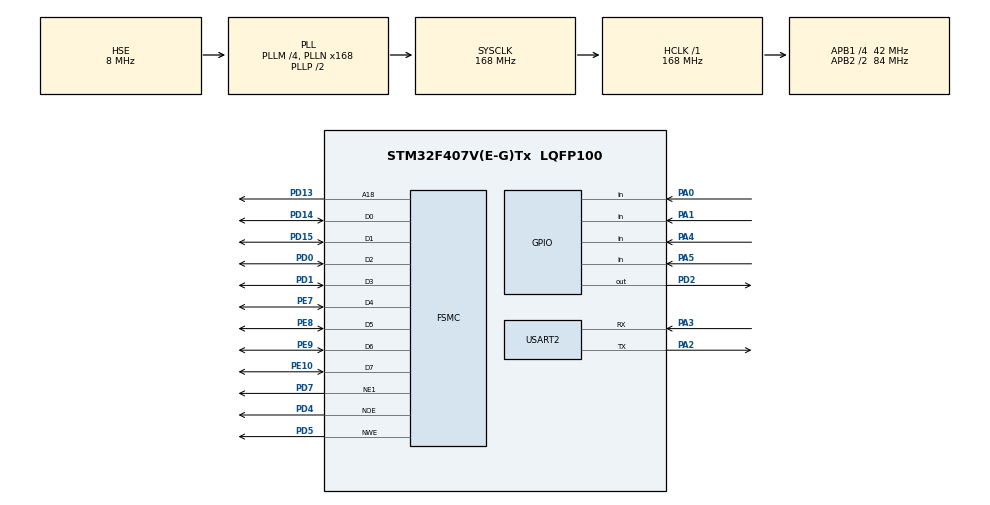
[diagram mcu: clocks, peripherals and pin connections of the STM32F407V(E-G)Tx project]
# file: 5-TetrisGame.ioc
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Mcu.Family=STM32F4
Mcu.Name=STM32F407V(E-G)Tx
Mcu.Package=LQFP100
NVIC.HASH_RNG_IRQn=true\:0\:0\:false\:false\:true\:true\:true
NVIC.PriorityGroup=NVIC_PRIORITYGROUP_4
NVIC.TIM2_IRQn=true\:0\:0\:false\:false\:true\:true\:true
PA0-WKUP.Signal=GPIO_Input
PA1.Signal=GPIO_Input
PA13.Mode=Serial_Wire
PA13.Signal=SYS_JTMS-SWDIO
PA14.Mode=Serial_Wire
PA14.Signal=SYS_JTCK-SWCLK
PA2.Mode=Asynchronous
PA2.Signal=USART2_TX
PA3.Mode=Asynchronous
PA3.Signal=USART2_RX
PA4.Signal=GPIO_Input
PA5.Signal=GPIO_Input
PD0.Mode=8b-d1
PD0.Signal=FSMC_D2
PD1.Mode=8b-d1
PD1.Signal=FSMC_D3
PD13.Mode=A18_1
PD13.Signal=FSMC_A18
PD14.Mode=8b-d1
PD14.Signal=FSMC_D0
PD15.Mode=8b-d1
PD15.Signal=FSMC_D1
PD2.Signal=GPIO_Output
PD4.Mode=Lcd1
PD4.Signal=FSMC_NOE
PD5.Mode=Lcd1
PD5.Signal=FSMC_NWE
PD7.Mode=NorPsramChipSelect1_1
PD7.Signal=FSMC_NE1
PE10.Mode=8b-d1
PE10.Signal=FSMC_D7
PE7.Mode=8b-d1
PE7.Signal=FSMC_D4
PE8.Mode=8b-d1
PE8.Signal=FSMC_D5
PE9.Mode=8b-d1
PE9.Signal=FSMC_D6
PH0-OSC_IN.Mode=HSE-External-Oscillator
PH0-OSC_IN.Signal=RCC_OSC_IN
PH1-OSC_OUT.Mode=HSE-External-Oscillator
PH1-OSC_OUT.Signal=RCC_OSC_OUT
ProjectManager.HeapSize=0x200
ProjectManager.StackSize=0x400
ProjectManager.TargetToolchain=TrueSTUDIO
RCC.48MHZClocksFreq_Value=48000000
RCC.AHBFreq_Value=168000000
RCC.APB1CLKDivider=RCC_HCLK_DIV4
RCC.APB1Freq_Value=42000000
RCC.APB1TimFreq_Value=84000000
RCC.APB2CLKDivider=RCC_HCLK_DIV2
RCC.APB2Freq_Value=84000000
RCC.APB2TimFreq_Value=168000000
RCC.CortexFreq_Value=168000000
RCC.HCLKFreq_Value=168000000
RCC.HSE_VALUE=8000000
RCC.HSI_VALUE=16000000
RCC.LSE_VALUE=32768
RCC.PLLM=4
RCC.PLLN=168
RCC.PLLQ=7
RCC.PLLSourceVirtual=RCC_PLLSOURCE_HSE
RCC.SYSCLKFreq_VALUE=168000000
RCC.SYSCLKSource=RCC_SYSCLKSOURCE_PLLCLK
RCC.VCOOutputFreq_Value=336000000
TIM2.Period=400
TIM2.Prescaler=16799
USART2.VirtualMode=VM_ASYNC
VP_RNG_VS_RNG.Mode=RNG_Activate
VP_TIM2_VS_ClockSourceINT.Mode=Internal
board=custom

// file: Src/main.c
/* USER CODE BEGIN Header */
/**
  ******************************************************************************
  * @file           : main.c
  * @brief          : Main program body
  ******************************************************************************
  * @attention
  *
  * <h2><center>&copy; Copyright (c) 2021 STMicroelectronics.
  * All rights reserved.</center></h2>
  *
  * This software component is licensed by ST under BSD 3-Clause license,
  * the "License"; You may not use this file except in compliance with the
  * License. You may obtain a copy of the License at:
  *                        opensource.org/licenses/BSD-3-Clause
  *
  ******************************************************************************
  */
/* USER CODE END Header */

#include "main.h"

/* USER CODE BEGIN Includes */
#include "ili9341.h"
/* USER CODE END Includes */

RNG_HandleTypeDef hrng;

TIM_HandleTypeDef htim2;

UART_HandleTypeDef huart2;

SRAM_HandleTypeDef hsram1;

void SystemClock_Config(void);
static void MX_GPIO_Init(void);
static void MX_FSMC_Init(void);
static void MX_TIM2_Init(void);
static void MX_USART2_UART_Init(void);
static void MX_RNG_Init(void);
/* USER CODE BEGIN PFP */
void tetrisGame();
/* USER CODE END PFP */

int main(void)
{

  /* MCU Configuration--------------------------------------------------------*/

  /* Reset of all peripherals, Initializes the Flash interface and the Systick. */
  HAL_Init();

  /* Configure the system clock */
  SystemClock_Config();

  /* Initialize all configured peripherals */
  MX_GPIO_Init();
  MX_FSMC_Init();
  MX_TIM2_Init();
  MX_USART2_UART_Init();
  MX_RNG_Init();
  /* USER CODE BEGIN 2 */
  tetrisGame();

  /* USER CODE END 2 */

  /* Infinite loop */
  while (1)
  {

  }
}

void SystemClock_Config(void)
{
  RCC_OscInitTypeDef RCC_OscInitStruct = {0};
  RCC_ClkInitTypeDef RCC_ClkInitStruct = {0};

  /** Configure the main internal regulator output voltage
  */
  __HAL_RCC_PWR_CLK_ENABLE();
  __HAL_PWR_VOLTAGESCALING_CONFIG(PWR_REGULATOR_VOLTAGE_SCALE1);
  /** Initializes the CPU, AHB and APB busses clocks
  */
  RCC_OscInitStruct.OscillatorType = RCC_OSCILLATORTYPE_HSE;
  RCC_OscInitStruct.HSEState = RCC_HSE_ON;
  RCC_OscInitStruct.PLL.PLLState = RCC_PLL_ON;
  RCC_OscInitStruct.PLL.PLLSource = RCC_PLLSOURCE_HSE;
  RCC_OscInitStruct.PLL.PLLM = 4;
  RCC_OscInitStruct.PLL.PLLN = 168;
  RCC_OscInitStruct.PLL.PLLP = RCC_PLLP_DIV2;
  RCC_OscInitStruct.PLL.PLLQ = 7;
  if (HAL_RCC_OscConfig(&RCC_OscInitStruct) != HAL_OK)
  {
    Error_Handler();
  }
  /** Initializes the CPU, AHB and APB busses clocks
  */
  RCC_ClkInitStruct.ClockType = RCC_CLOCKTYPE_HCLK|RCC_CLOCKTYPE_SYSCLK
                              |RCC_CLOCKTYPE_PCLK1|RCC_CLOCKTYPE_PCLK2;
  RCC_ClkInitStruct.SYSCLKSource = RCC_SYSCLKSOURCE_PLLCLK;
  RCC_ClkInitStruct.AHBCLKDivider = RCC_SYSCLK_DIV1;
  RCC_ClkInitStruct.APB1CLKDivider = RCC_HCLK_DIV4;
  RCC_ClkInitStruct.APB2CLKDivider = RCC_HCLK_DIV2;

  if (HAL_RCC_ClockConfig(&RCC_ClkInitStruct, FLASH_LATENCY_5) != HAL_OK)
  {
    Error_Handler();
  }
}

static void MX_RNG_Init(void)
{

  hrng.Instance = RNG;
  if (HAL_RNG_Init(&hrng) != HAL_OK)
  {
    Error_Handler();
  }

}

static void MX_TIM2_Init(void)
{

  TIM_ClockConfigTypeDef sClockSourceConfig = {0};
  TIM_MasterConfigTypeDef sMasterConfig = {0};

  htim2.Instance = TIM2;
  htim2.Init.Prescaler = 16799;
  htim2.Init.CounterMode = TIM_COUNTERMODE_UP;
  htim2.Init.Period = 400;
  htim2.Init.ClockDivision = TIM_CLOCKDIVISION_DIV1;
  htim2.Init.AutoReloadPreload = TIM_AUTORELOAD_PRELOAD_DISABLE;
  if (HAL_TIM_Base_Init(&htim2) != HAL_OK)
  {
    Error_Handler();
  }
  sClockSourceConfig.ClockSource = TIM_CLOCKSOURCE_INTERNAL;
  if (HAL_TIM_ConfigClockSource(&htim2, &sClockSourceConfig) != HAL_OK)
  {
    Error_Handler();
  }
  sMasterConfig.MasterOutputTrigger = TIM_TRGO_RESET;
  sMasterConfig.MasterSlaveMode = TIM_MASTERSLAVEMODE_DISABLE;
  if (HAL_TIMEx_MasterConfigSynchronization(&htim2, &sMasterConfig) != HAL_OK)
  {
    Error_Handler();
  }

}

static void MX_USART2_UART_Init(void)
{

  huart2.Instance = USART2;
  huart2.Init.BaudRate = 115200;
  huart2.Init.WordLength = UART_WORDLENGTH_8B;
  huart2.Init.StopBits = UART_STOPBITS_1;
  huart2.Init.Parity = UART_PARITY_NONE;
  huart2.Init.Mode = UART_MODE_TX_RX;
  huart2.Init.HwFlowCtl = UART_HWCONTROL_NONE;
  huart2.Init.OverSampling = UART_OVERSAMPLING_16;
  if (HAL_UART_Init(&huart2) != HAL_OK)
  {
    Error_Handler();
  }

}

static void MX_GPIO_Init(void)
{
  GPIO_InitTypeDef GPIO_InitStruct = {0};

  /* GPIO Ports Clock Enable */
  __HAL_RCC_GPIOH_CLK_ENABLE();
  __HAL_RCC_GPIOA_CLK_ENABLE();
  __HAL_RCC_GPIOE_CLK_ENABLE();
  __HAL_RCC_GPIOD_CLK_ENABLE();

  /*Configure GPIO pin Output Level */
  HAL_GPIO_WritePin(GPIOD, GPIO_PIN_2, GPIO_PIN_RESET);

  /*Configure GPIO pins : PA0 PA1 PA4 PA5 */
  GPIO_InitStruct.Pin = GPIO_PIN_0|GPIO_PIN_1|GPIO_PIN_4|GPIO_PIN_5;
  GPIO_InitStruct.Mode = GPIO_MODE_INPUT;
  GPIO_InitStruct.Pull = GPIO_NOPULL;
  HAL_GPIO_Init(GPIOA, &GPIO_InitStruct);

  /*Configure GPIO pin : PD2 */
  GPIO_InitStruct.Pin = GPIO_PIN_2;
  GPIO_InitStruct.Mode = GPIO_MODE_OUTPUT_PP;
  GPIO_InitStruct.Pull = GPIO_NOPULL;
  GPIO_InitStruct.Speed = GPIO_SPEED_FREQ_LOW;
  HAL_GPIO_Init(GPIOD, &GPIO_InitStruct);

}

/* FSMC initialization function */
static void MX_FSMC_Init(void)
{

  FSMC_NORSRAM_TimingTypeDef Timing = {0};

  /** Perform the SRAM1 memory initialization sequence
  */
  hsram1.Instance = FSMC_NORSRAM_DEVICE;
  hsram1.Extended = FSMC_NORSRAM_EXTENDED_DEVICE;
  /* hsram1.Init */
  hsram1.Init.NSBank = FSMC_NORSRAM_BANK1;
  hsram1.Init.DataAddressMux = FSMC_DATA_ADDRESS_MUX_DISABLE;
  hsram1.Init.MemoryType = FSMC_MEMORY_TYPE_SRAM;
  hsram1.Init.MemoryDataWidth = FSMC_NORSRAM_MEM_BUS_WIDTH_8;
  hsram1.Init.BurstAccessMode = FSMC_BURST_ACCESS_MODE_DISABLE;
  hsram1.Init.WaitSignalPolarity = FSMC_WAIT_SIGNAL_POLARITY_LOW;
  hsram1.Init.WrapMode = FSMC_WRAP_MODE_DISABLE;
  hsram1.Init.WaitSignalActive = FSMC_WAIT_TIMING_BEFORE_WS;
  hsram1.Init.WriteOperation = FSMC_WRITE_OPERATION_ENABLE;
  hsram1.Init.WaitSignal = FSMC_WAIT_SIGNAL_DISABLE;
  hsram1.Init.ExtendedMode = FSMC_EXTENDED_MODE_DISABLE;
  hsram1.Init.AsynchronousWait = FSMC_ASYNCHRONOUS_WAIT_DISABLE;
  hsram1.Init.WriteBurst = FSMC_WRITE_BURST_DISABLE;
  hsram1.Init.PageSize = FSMC_PAGE_SIZE_NONE;
  /* Timing */
  Timing.AddressSetupTime = 15;
  Timing.AddressHoldTime = 15;
  Timing.DataSetupTime = 255;
  Timing.BusTurnAroundDuration = 15;
  Timing.CLKDivision = 16;
  Timing.DataLatency = 17;
  Timing.AccessMode = FSMC_ACCESS_MODE_A;
  /* ExtTiming */

  if (HAL_SRAM_Init(&hsram1, &Timing, NULL) != HAL_OK)
  {
    Error_Handler( );
  }

}

void Error_Handler(void)
{
}

/************************ (C) COPYRIGHT STMicroelectronics *****END OF FILE****/
